VERSION "HIPBNYYYYYYYYYYYYYYYYYYYYYYYYYYYYYYYYYYYYY/4/%%%/4/'%**4YYY///"

NS_ :

BS_:

BU_:

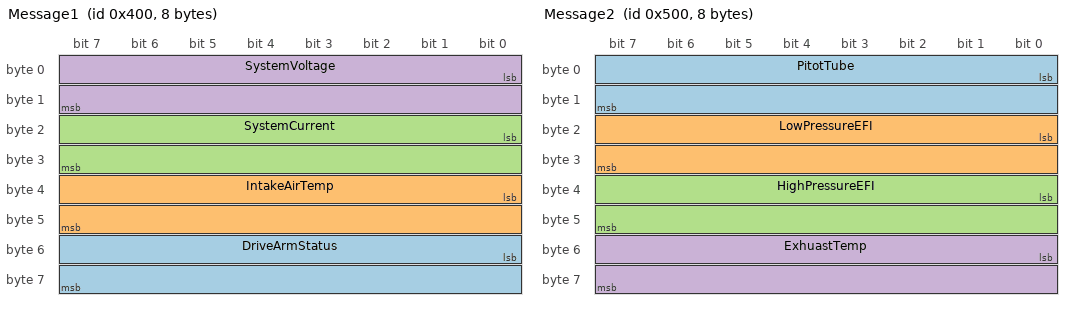
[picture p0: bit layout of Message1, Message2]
BO_ 1024 Message1: 8 Vector__XXX
 SG_ DriveArmStatus : 48|16@1+ (1,0) [0|0] "" Vector__XXX
 SG_ IntakeAirTemp : 32|16@1+ (1,0) [0|0] "" Vector__XXX
 SG_ SystemCurrent : 16|16@1+ (1,0) [0|0] "" Vector__XXX
 SG_ SystemVoltage : 0|16@1+ (1,0) [0|0] "" Vector__XXX

BO_ 1280 Message2: 8 Vector__XXX
 SG_ PitotTube : 0|16@1+ (1,0) [0|0] "" Vector__XXX
 SG_ LowPressureEFI : 16|16@1+ (1,0) [0|0] "" Vector__XXX
 SG_ HighPressureEFI : 32|16@1+ (1,0) [0|0] "" Vector__XXX
 SG_ ExhuastTemp : 48|16@1+ (1,0) [0|0] "" Vector__XXX

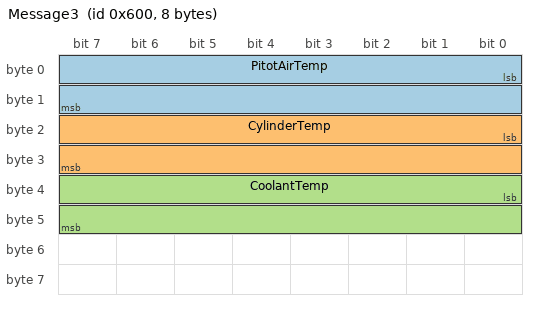
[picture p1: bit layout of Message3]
BO_ 1536 Message3: 8 Vector__XXX
 SG_ PitotAirTemp : 0|16@1+ (1,0) [0|0] "" Vector__XXX
 SG_ CylinderTemp : 16|16@1+ (1,0) [0|0] "" Vector__XXX
 SG_ CoolantTemp : 32|16@1+ (1,0) [0|0] "" Vector__XXX

BO_ 1792 Message4: 8 Vector__XXX
 SG_ EngineTachPulse : 0|32@1+ (1,0) [0|0] "" Vector__XXX
 SG_ WheelTachPulse : 32|32@1+ (1,0) [0|0] "" Vector__XXX
